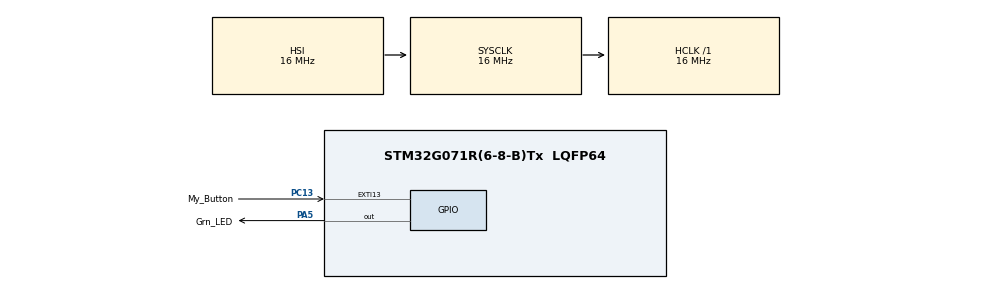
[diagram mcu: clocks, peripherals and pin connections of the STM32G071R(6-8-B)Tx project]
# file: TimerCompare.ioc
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Mcu.Family=STM32G0
Mcu.Name=STM32G071R(6-8-B)Tx
Mcu.Package=LQFP64
NVIC.EXTI4_15_IRQn=true\:0\:0\:false\:false\:true\:true\:true\:true
NVIC.TIM3_IRQn=true\:0\:0\:false\:false\:true\:true\:true\:true
PA5.GPIO_Label=Grn_LED
PA5.Signal=GPIO_Output
PC13.GPIO_Label=My_Button
PC13.Signal=GPXTI13
ProjectManager.HeapSize=0x200
ProjectManager.StackSize=0x400
ProjectManager.TargetToolchain=STM32CubeIDE
RCC.AHBFreq_Value=16000000
RCC.CortexFreq_Value=16000000
RCC.EXTERNAL_CLOCK_VALUE=48000
RCC.HCLKFreq_Value=16000000
RCC.HSE_VALUE=8000000
RCC.HSI_VALUE=16000000
RCC.LSE_VALUE=32768
RCC.SYSCLKFreq_VALUE=16000000
RCC.VCOOutputFreq_Value=128000000
TIM3.Period=31249
TIM3.Prescaler=127
TIM3.TIM_MasterOutputTrigger=TIM_TRGO_UPDATE
VP_TIM3_VS_ClockSourceINT.Mode=Internal
board=custom

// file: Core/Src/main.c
/* USER CODE BEGIN Header */
/**
  ******************************************************************************
  * @file           : main.c
  * @brief          : Main program body
  ******************************************************************************
  * @attention
  *
  * Copyright (c) 2024 STMicroelectronics.
  * All rights reserved.
  *
  * This software is licensed under terms that can be found in the LICENSE file
  * in the root directory of this software component.
  * If no LICENSE file comes with this software, it is provided AS-IS.
  *
  ******************************************************************************
  */
/* USER CODE END Header */
#include "main.h"

TIM_HandleTypeDef htim3;

/* USER CODE BEGIN PV */
volatile uint8_t timerRunning = 1;
/* USER CODE END PV */

void SystemClock_Config(void);
static void MX_GPIO_Init(void);
static void MX_TIM3_Init(void);

int main(void)
{

  /* MCU Configuration--------------------------------------------------------*/

  /* Reset of all peripherals, Initializes the Flash interface and the Systick. */
  HAL_Init();

  /* Configure the system clock */
  SystemClock_Config();

  /* Initialize all configured peripherals */
  MX_GPIO_Init();
  MX_TIM3_Init();
  /* USER CODE BEGIN 2 */
  if(HAL_TIM_Base_Start_IT(&htim3)!=HAL_OK){
	  Error_Handler();
  }
//&htim3 - timer3
  /* USER CODE END 2 */

  /* Infinite loop */
  while (1)
  {

  }
}

void SystemClock_Config(void)
{
  RCC_OscInitTypeDef RCC_OscInitStruct = {0};
  RCC_ClkInitTypeDef RCC_ClkInitStruct = {0};

  /** Configure the main internal regulator output voltage
  */
  HAL_PWREx_ControlVoltageScaling(PWR_REGULATOR_VOLTAGE_SCALE1);

  /** Initializes the RCC Oscillators according to the specified parameters
  * in the RCC_OscInitTypeDef structure.
  */
  RCC_OscInitStruct.OscillatorType = RCC_OSCILLATORTYPE_HSI;
  RCC_OscInitStruct.HSIState = RCC_HSI_ON;
  RCC_OscInitStruct.HSIDiv = RCC_HSI_DIV1;
  RCC_OscInitStruct.HSICalibrationValue = RCC_HSICALIBRATION_DEFAULT;
  RCC_OscInitStruct.PLL.PLLState = RCC_PLL_NONE;
  if (HAL_RCC_OscConfig(&RCC_OscInitStruct) != HAL_OK)
  {
    Error_Handler();
  }

  /** Initializes the CPU, AHB and APB buses clocks
  */
  RCC_ClkInitStruct.ClockType = RCC_CLOCKTYPE_HCLK|RCC_CLOCKTYPE_SYSCLK
                              |RCC_CLOCKTYPE_PCLK1;
  RCC_ClkInitStruct.SYSCLKSource = RCC_SYSCLKSOURCE_HSI;
  RCC_ClkInitStruct.AHBCLKDivider = RCC_SYSCLK_DIV1;
  RCC_ClkInitStruct.APB1CLKDivider = RCC_HCLK_DIV1;

  if (HAL_RCC_ClockConfig(&RCC_ClkInitStruct, FLASH_LATENCY_0) != HAL_OK)
  {
    Error_Handler();
  }
}

static void MX_TIM3_Init(void)
{

  TIM_ClockConfigTypeDef sClockSourceConfig = {0};
  TIM_MasterConfigTypeDef sMasterConfig = {0};

  htim3.Instance = TIM3;
  htim3.Init.Prescaler = 127;
  htim3.Init.CounterMode = TIM_COUNTERMODE_UP;
  htim3.Init.Period = 31249;
  htim3.Init.ClockDivision = TIM_CLOCKDIVISION_DIV1;
  htim3.Init.AutoReloadPreload = TIM_AUTORELOAD_PRELOAD_DISABLE;
  if (HAL_TIM_Base_Init(&htim3) != HAL_OK)
  {
    Error_Handler();
  }
  sClockSourceConfig.ClockSource = TIM_CLOCKSOURCE_INTERNAL;
  if (HAL_TIM_ConfigClockSource(&htim3, &sClockSourceConfig) != HAL_OK)
  {
    Error_Handler();
  }
  sMasterConfig.MasterOutputTrigger = TIM_TRGO_UPDATE;
  sMasterConfig.MasterSlaveMode = TIM_MASTERSLAVEMODE_DISABLE;
  if (HAL_TIMEx_MasterConfigSynchronization(&htim3, &sMasterConfig) != HAL_OK)
  {
    Error_Handler();
  }

}

static void MX_GPIO_Init(void)
{
  GPIO_InitTypeDef GPIO_InitStruct = {0};

  /* GPIO Ports Clock Enable */
  __HAL_RCC_GPIOC_CLK_ENABLE();
  __HAL_RCC_GPIOA_CLK_ENABLE();

  /*Configure GPIO pin Output Level */
  HAL_GPIO_WritePin(Grn_LED_GPIO_Port, Grn_LED_Pin, GPIO_PIN_RESET);

  /*Configure GPIO pin : My_Button_Pin */
  GPIO_InitStruct.Pin = My_Button_Pin;
  GPIO_InitStruct.Mode = GPIO_MODE_IT_RISING;
  GPIO_InitStruct.Pull = GPIO_NOPULL;
  HAL_GPIO_Init(My_Button_GPIO_Port, &GPIO_InitStruct);

  /*Configure GPIO pin : Grn_LED_Pin */
  GPIO_InitStruct.Pin = Grn_LED_Pin;
  GPIO_InitStruct.Mode = GPIO_MODE_OUTPUT_PP;
  GPIO_InitStruct.Pull = GPIO_NOPULL;
  GPIO_InitStruct.Speed = GPIO_SPEED_FREQ_LOW;
  HAL_GPIO_Init(Grn_LED_GPIO_Port, &GPIO_InitStruct);

  /* EXTI interrupt init*/
  HAL_NVIC_SetPriority(EXTI4_15_IRQn, 0, 0);
  HAL_NVIC_EnableIRQ(EXTI4_15_IRQn);

}

/* USER CODE BEGIN 4 */

void HAL_TIM_PeriodElapsedCallback(TIM_HandleTypeDef *htim){
	if(htim->Instance ==TIM3){
		HAL_GPIO_TogglePin(Grn_LED_GPIO_Port, Grn_LED_Pin);

}
}

void HAL_GPIO_EXTI_Rising_Callback(uint16_t GPIO_Pin)
{
  if (GPIO_Pin == My_Button_Pin) {
    timerRunning = !timerRunning;

    if (timerRunning) {
      HAL_TIM_Base_Start_IT(&htim3);  // Resume Timer
    } else {
      HAL_TIM_Base_Stop_IT(&htim3);   // Stop Timer
    }
  }
}

/* USER CODE END 4 */

void Error_Handler(void)
{
  __disable_irq();
  while (1)
  {
  }
}
